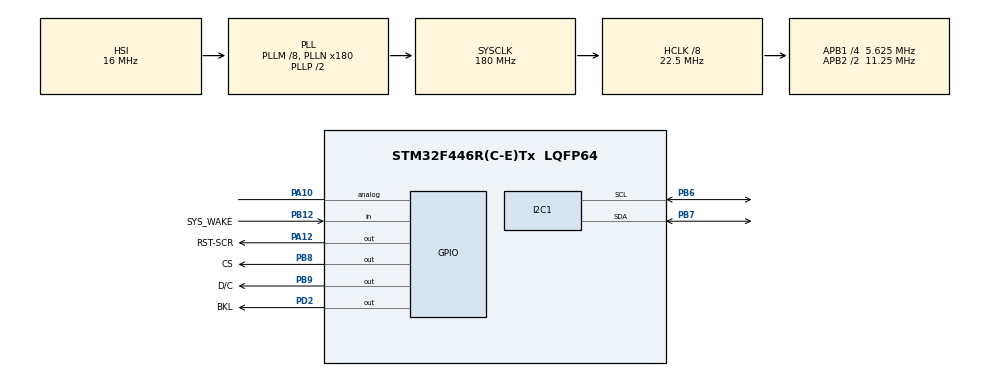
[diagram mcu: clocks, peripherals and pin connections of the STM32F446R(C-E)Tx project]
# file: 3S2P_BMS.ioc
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FREERTOS.Events01=myEvent01,Dynamic,NULL
FREERTOS.Tasks01=defaultTask,24,128,StartDefaultTask,Default,NULL,Dynamic,NULL,NULL
FREERTOS.configUSE_NEWLIB_REENTRANT=1
FREERTOS.configUSE_STATS_FORMATTING_FUNCTIONS=1
I2C1.NoStretchMode=I2C_NOSTRETCH_ENABLE
Mcu.Family=STM32F4
Mcu.Name=STM32F446R(C-E)Tx
Mcu.Package=LQFP64
NVIC.PriorityGroup=NVIC_PRIORITYGROUP_4
NVIC.TIM2_IRQn=true\:15\:0\:false\:false\:true\:false\:false\:true\:true
NVIC.TimeBase=TIM2_IRQn
NVIC.TimeBaseIP=TIM2
PA10.Signal=GPIO_Analog
PA12.GPIO_Label=RST-SCR
PA12.Signal=GPIO_Output
PA13.Mode=Serial_Wire
PA13.Signal=SYS_JTMS-SWDIO
PA14.Mode=Serial_Wire
PA14.Signal=SYS_JTCK-SWCLK
PB12.GPIO_Label=SYS_WAKE
PB12.Signal=GPIO_Input
PB3.Signal=SPI1_SCK
PB4.Signal=SPI1_MISO
PB5.Signal=SPI1_MOSI
PB6.Mode=I2C
PB6.Signal=I2C1_SCL
PB7.Mode=I2C
PB7.Signal=I2C1_SDA
PB8.GPIO_Label=CS
PB8.Signal=GPIO_Output
PB9.GPIO_Label=D/C
PB9.Signal=GPIO_Output
PC1.Signal=ADCx_IN11
PD2.GPIO_Label=BKL
PD2.GPIO_ModeDefaultOutputPP=GPIO_MODE_OUTPUT_PP
PD2.GPIO_PuPd=GPIO_NOPULL
PD2.PinState=GPIO_PIN_RESET
PD2.Signal=GPIO_Output
PH0-OSC_IN.Mode=HSE-External-Oscillator
PH0-OSC_IN.Signal=RCC_OSC_IN
PH1-OSC_OUT.Mode=HSE-External-Oscillator
PH1-OSC_OUT.Signal=RCC_OSC_OUT
ProjectManager.HeapSize=0x200
ProjectManager.StackSize=0x400
ProjectManager.TargetToolchain=STM32CubeIDE
RCC.AHBCLKDivider=RCC_SYSCLK_DIV8
RCC.AHBFreq_Value=22500000
RCC.APB1CLKDivider=RCC_HCLK_DIV4
RCC.APB1Freq_Value=5625000
RCC.APB1TimFreq_Value=11250000
RCC.APB2CLKDivider=RCC_HCLK_DIV2
RCC.APB2Freq_Value=11250000
RCC.APB2TimFreq_Value=22500000
RCC.CortexFreq_Value=22500000
RCC.HCLKFreq_Value=22500000
RCC.PLLM=8
RCC.PLLN=180
RCC.SYSCLKFreq_VALUE=180000000
RCC.SYSCLKSource=RCC_SYSCLKSOURCE_PLLCLK
RCC.USBFreq_Value=180000000
RCC.VCOOutputFreq_Value=360000000
SH.ADCx_IN11.0=ADC1_IN11
VP_FREERTOS_VS_CMSIS_V2.Mode=CMSIS_V2
VP_SYS_VS_tim2.Mode=TIM2
board=custom

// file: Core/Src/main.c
/* USER CODE BEGIN Header */
/**
  ******************************************************************************
  * @file           : main.c
  * @brief          : Main program body
  ******************************************************************************
  * @attention
  *
  * Copyright (c) 2024 STMicroelectronics.
  * All rights reserved.
  *
  * This software is licensed under terms that can be found in the LICENSE file
  * in the root directory of this software component.
  * If no LICENSE file comes with this software, it is provided AS-IS.
  *
  ******************************************************************************
  */
/* USER CODE END Header */
#include "main.h"
#include "cmsis_os.h"
#include "i2c.h"
#include "gpio.h"

/* USER CODE BEGIN Includes */
#include "bq76952.h"
/* USER CODE END Includes */

void SystemClock_Config(void);
void MX_FREERTOS_Init(void);

/* USER CODE BEGIN 0 */
void delay_us(uint32_t Delay)
{
	uint32_t cnt = Delay*8;
	uint32_t i =0;
	for(i = 0;i<cnt; i++)
		__NOP();
}
/* USER CODE END 0 */

int main(void)
{

  /* MCU Configuration--------------------------------------------------------*/

  /* Reset of all peripherals, Initializes the Flash interface and the Systick. */
  HAL_Init();

  /* USER CODE BEGIN Init */
//  lv_init();
  /* USER CODE END Init */

  /* Configure the system clock */
  SystemClock_Config();

  /* Initialize all configured peripherals */
  MX_GPIO_Init();
  MX_I2C1_Init();

  /* Init scheduler */
  osKernelInitialize();

  /* Call init function for freertos objects (in cmsis_os2.c) */
  MX_FREERTOS_Init();

  /* Start scheduler */
  osKernelStart();

  /* We should never get here as control is now taken by the scheduler */

  /* Infinite loop */
  /* USER CODE BEGIN WHILE */
  while (1)
  {
//	  read_cell_1();
    /* USER CODE END WHILE */

  }
}

void SystemClock_Config(void)
{
  RCC_OscInitTypeDef RCC_OscInitStruct = {0};
  RCC_ClkInitTypeDef RCC_ClkInitStruct = {0};

  /** Configure the main internal regulator output voltage
  */
  __HAL_RCC_PWR_CLK_ENABLE();
  __HAL_PWR_VOLTAGESCALING_CONFIG(PWR_REGULATOR_VOLTAGE_SCALE3);

  /** Initializes the RCC Oscillators according to the specified parameters
  * in the RCC_OscInitTypeDef structure.
  */
  RCC_OscInitStruct.OscillatorType = RCC_OSCILLATORTYPE_HSI;
  RCC_OscInitStruct.HSIState = RCC_HSI_ON;
  RCC_OscInitStruct.HSICalibrationValue = RCC_HSICALIBRATION_DEFAULT;
  RCC_OscInitStruct.PLL.PLLState = RCC_PLL_ON;
  RCC_OscInitStruct.PLL.PLLSource = RCC_PLLSOURCE_HSI;
  RCC_OscInitStruct.PLL.PLLM = 8;
  RCC_OscInitStruct.PLL.PLLN = 180;
  RCC_OscInitStruct.PLL.PLLP = RCC_PLLP_DIV2;
  RCC_OscInitStruct.PLL.PLLQ = 2;
  RCC_OscInitStruct.PLL.PLLR = 2;
  if (HAL_RCC_OscConfig(&RCC_OscInitStruct) != HAL_OK)
  {
    Error_Handler();
  }

  /** Initializes the CPU, AHB and APB buses clocks
  */
  RCC_ClkInitStruct.ClockType = RCC_CLOCKTYPE_HCLK|RCC_CLOCKTYPE_SYSCLK
                              |RCC_CLOCKTYPE_PCLK1|RCC_CLOCKTYPE_PCLK2;
  RCC_ClkInitStruct.SYSCLKSource = RCC_SYSCLKSOURCE_PLLCLK;
  RCC_ClkInitStruct.AHBCLKDivider = RCC_SYSCLK_DIV8;
  RCC_ClkInitStruct.APB1CLKDivider = RCC_HCLK_DIV4;
  RCC_ClkInitStruct.APB2CLKDivider = RCC_HCLK_DIV2;

  if (HAL_RCC_ClockConfig(&RCC_ClkInitStruct, FLASH_LATENCY_0) != HAL_OK)
  {
    Error_Handler();
  }
}

void HAL_TIM_PeriodElapsedCallback(TIM_HandleTypeDef *htim)
{
  if (htim->Instance == TIM2) {
    HAL_IncTick();
  }
}

void Error_Handler(void)
{
  __disable_irq();
  while (1)
  {
  }
}

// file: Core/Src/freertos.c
/* USER CODE BEGIN Header */
/**
  ******************************************************************************
  * File Name          : freertos.c
  * Description        : Code for freertos applications
  ******************************************************************************
  * @attention
  *
  * Copyright (c) 2024 STMicroelectronics.
  * All rights reserved.
  *
  * This software is licensed under terms that can be found in the LICENSE file
  * in the root directory of this software component.
  * If no LICENSE file comes with this software, it is provided AS-IS.
  *
  ******************************************************************************
  */
/* USER CODE END Header */

#include "FreeRTOS.h"
#include "task.h"
#include "main.h"
#include "cmsis_os.h"

/* USER CODE BEGIN Includes */
#include "bq76952.h"
/* USER CODE END Includes */

/* Definitions for defaultTask */
osThreadId_t defaultTaskHandle;
const osThreadAttr_t defaultTask_attributes = {
  .name = "defaultTask",
  .stack_size = 128 * 4,
  .priority = (osPriority_t) osPriorityNormal,
};
/* Definitions for myEvent01 */
osEventFlagsId_t myEvent01Handle;
const osEventFlagsAttr_t myEvent01_attributes = {
  .name = "myEvent01"
};

void StartDefaultTask(void *argument);

void MX_FREERTOS_Init(void); /* (MISRA C 2004 rule 8.1) */

void MX_FREERTOS_Init(void) {

  /* Create the thread(s) */
  /* creation of defaultTask */
  defaultTaskHandle = osThreadNew(StartDefaultTask, NULL, &defaultTask_attributes);

  /* Create the event(s) */
  /* creation of myEvent01 */
  myEvent01Handle = osEventFlagsNew(&myEvent01_attributes);

}

void StartDefaultTask(void *argument)
{
  /* USER CODE BEGIN StartDefaultTask */
  /* Infinite loop */
  for(;;)
  {
	  osDelay(20);
	  read_cell_1();
  }
  /* USER CODE END StartDefaultTask */
}
